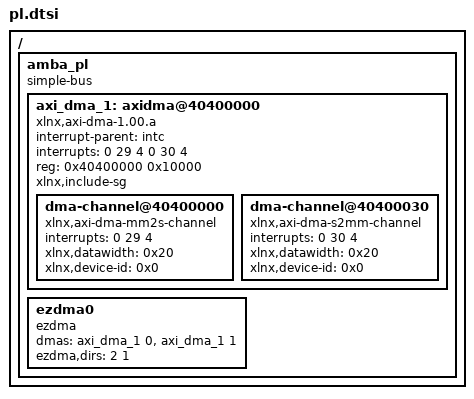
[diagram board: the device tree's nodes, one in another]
/*
 * CAUTION: This file is automatically generated by Xilinx.
 * Version:  
 * Today is: Tue Nov  8 18:58:00 2016
*/


/ {
	amba_pl: amba_pl {
		#address-cells = <1>;
		#size-cells = <1>;
		compatible = "simple-bus";
		ranges ;
		axi_dma_1: axidma@40400000 {
			#dma-cells = <1>;
			compatible = "xlnx,axi-dma-1.00.a";
			interrupt-parent = <&intc>;
			interrupts = <0 29 4 0 30 4>;
			reg = <0x40400000 0x10000>;
			xlnx,include-sg ;
			dma-channel@40400000 {
				compatible = "xlnx,axi-dma-mm2s-channel";
				interrupts = <0 29 4>;
				xlnx,datawidth = <0x20>;
				xlnx,device-id = <0x0>;
			};
			dma-channel@40400030 {
				compatible = "xlnx,axi-dma-s2mm-channel";
				interrupts = <0 30 4>;
				xlnx,datawidth = <0x20>;
				xlnx,device-id = <0x0>;
			};
		};
		ezdma0 {
	        compatible = "ezdma";
	
	        dmas = <&axi_dma_1 0 &axi_dma_1 1>;
	        dma-names = "axidma0", "axidma1";   // used when obtaining reference to above DMA core using dma_request_slave_channel()
	        ezdma,dirs = <2 1>;                 // direction of DMA channel: 1 = RX (dev->cpu), 2 = TX (cpu->dev)
    	};
	};
};
